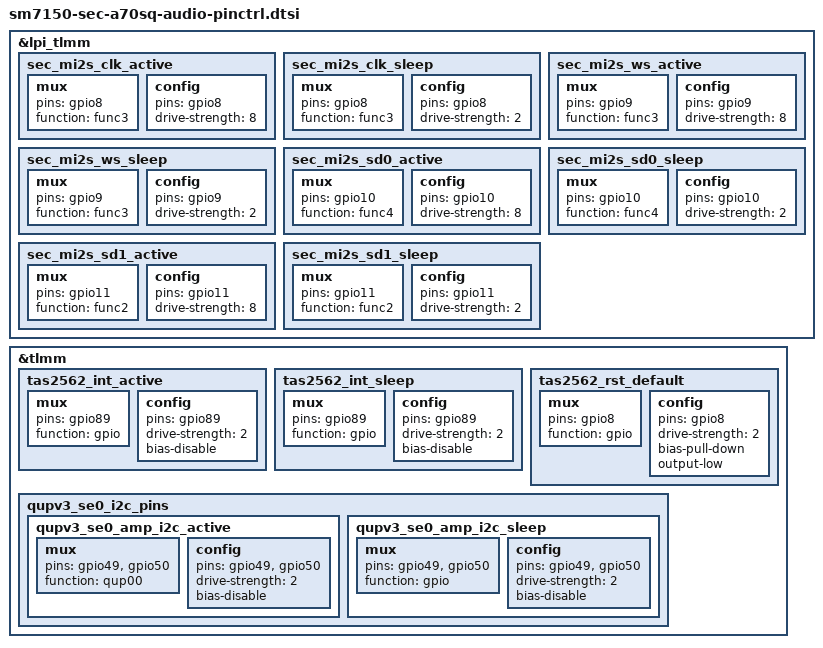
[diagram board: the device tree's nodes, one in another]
/* Copyright (c) 2016-2018, The Linux Foundation. All rights reserved.
 *
 * This program is free software; you can redistribute it and/or modify
 * it under the terms of the GNU General Public License version 2 and
 * only version 2 as published by the Free Software Foundation.
 *
 * This program is distributed in the hope that it will be useful,
 * but WITHOUT ANY WARRANTY; without even the implied warranty of
 * MERCHANTABILITY or FITNESS FOR A PARTICULAR PURPOSE.  See the
 * GNU General Public License for more details.
 */

&lpi_tlmm  {
	sec_mi2s_clk_active: sec_mi2s_clk_active {
		mux {
			pins = "gpio8";
			function = "func3";
		};
		config {
			pins = "gpio8";
			drive-strength = <8>;
		};
	};
	sec_mi2s_clk_sleep: sec_mi2s_clk_sleep {
		mux {
			pins = "gpio8";
			function = "func3";
		};
		config {
			pins = "gpio8";
			drive-strength = <2>;
		};
	};

	sec_mi2s_ws_active: sec_mi2s_ws_active {
		mux {
			pins = "gpio9";
			function = "func3";
		};
		config {
			pins = "gpio9";
			drive-strength = <8>;
		};
	};

	sec_mi2s_ws_sleep: sec_mi2s_ws_sleep {
		mux {
			pins = "gpio9";
			function = "func3";
		};
		config {
			pins = "gpio9";
			drive-strength = <2>;
		};
	};

	sec_mi2s_sd0_active: sec_mi2s_sd0_active {
		mux {
			pins = "gpio10";
			function = "func4";
		};

		config {
			pins = "gpio10";
			drive-strength = <8>;
		};
	};

	sec_mi2s_sd0_sleep: sec_mi2s_sd0_sleep {
		mux {
			pins = "gpio10";
			function = "func4";
		};
		config {
			pins = "gpio10";
			drive-strength = <2>;
		};
	};

	sec_mi2s_sd1_active: sec_mi2s_sd1_active {
		mux {
			pins = "gpio11";
			function = "func2";
		};
		config {
			pins = "gpio11";
			drive-strength = <8>;
		};
	};

	sec_mi2s_sd1_sleep: sec_mi2s_sd1_sleep {
		mux {
			pins = "gpio11";
			function = "func2";
		};
		config {
			pins = "gpio11";
			drive-strength = <2>;
		};
	};
};

&tlmm {
	/* TAS2562 speaker pins */
	tas2562_int_active: tas2562_int_active {
		mux {
			pins = "gpio89";
			function = "gpio";
		};
		config {
			pins = "gpio89";
			drive-strength = <2>; /* 2 MA */
			bias-disable; /* No PULL */
		};
	};

	tas2562_int_sleep: tas2562_int_sleep {
		mux {
			pins = "gpio89";
			function = "gpio";
		};
		config {
			pins = "gpio89";
			drive-strength = <2>; /* 2 MA */
			bias-disable; /* No PULL */
		};
	};

	tas2562_rst_default: tas2562_rst_default {
		mux {
			pins = "gpio8";
			function = "gpio";
		};
		config {
			pins = "gpio8";
			drive-strength = <2>; /* 2 MA */
			bias-pull-down; /* PULL DOWN*/
			output-low;
		};
	};

	/delete-node/ qupv3_se0_i2c_pins;
	qupv3_se0_i2c_pins: qupv3_se0_i2c_pins {
		qupv3_se0_amp_i2c_active: qupv3_se0_amp_i2c_active {
			mux {
				pins = "gpio49", "gpio50";
				function = "qup00";
			};

			config {
				pins = "gpio49", "gpio50";
				drive-strength = <2>;
				bias-disable;
			};
		};

		qupv3_se0_amp_i2c_sleep: qupv3_se0_amp_i2c_sleep {
			mux {
				pins = "gpio49", "gpio50";
				function = "gpio";
			};

			config {
				pins = "gpio49", "gpio50";
				drive-strength = <2>;
				bias-disable;
			};
		};
	};
};

